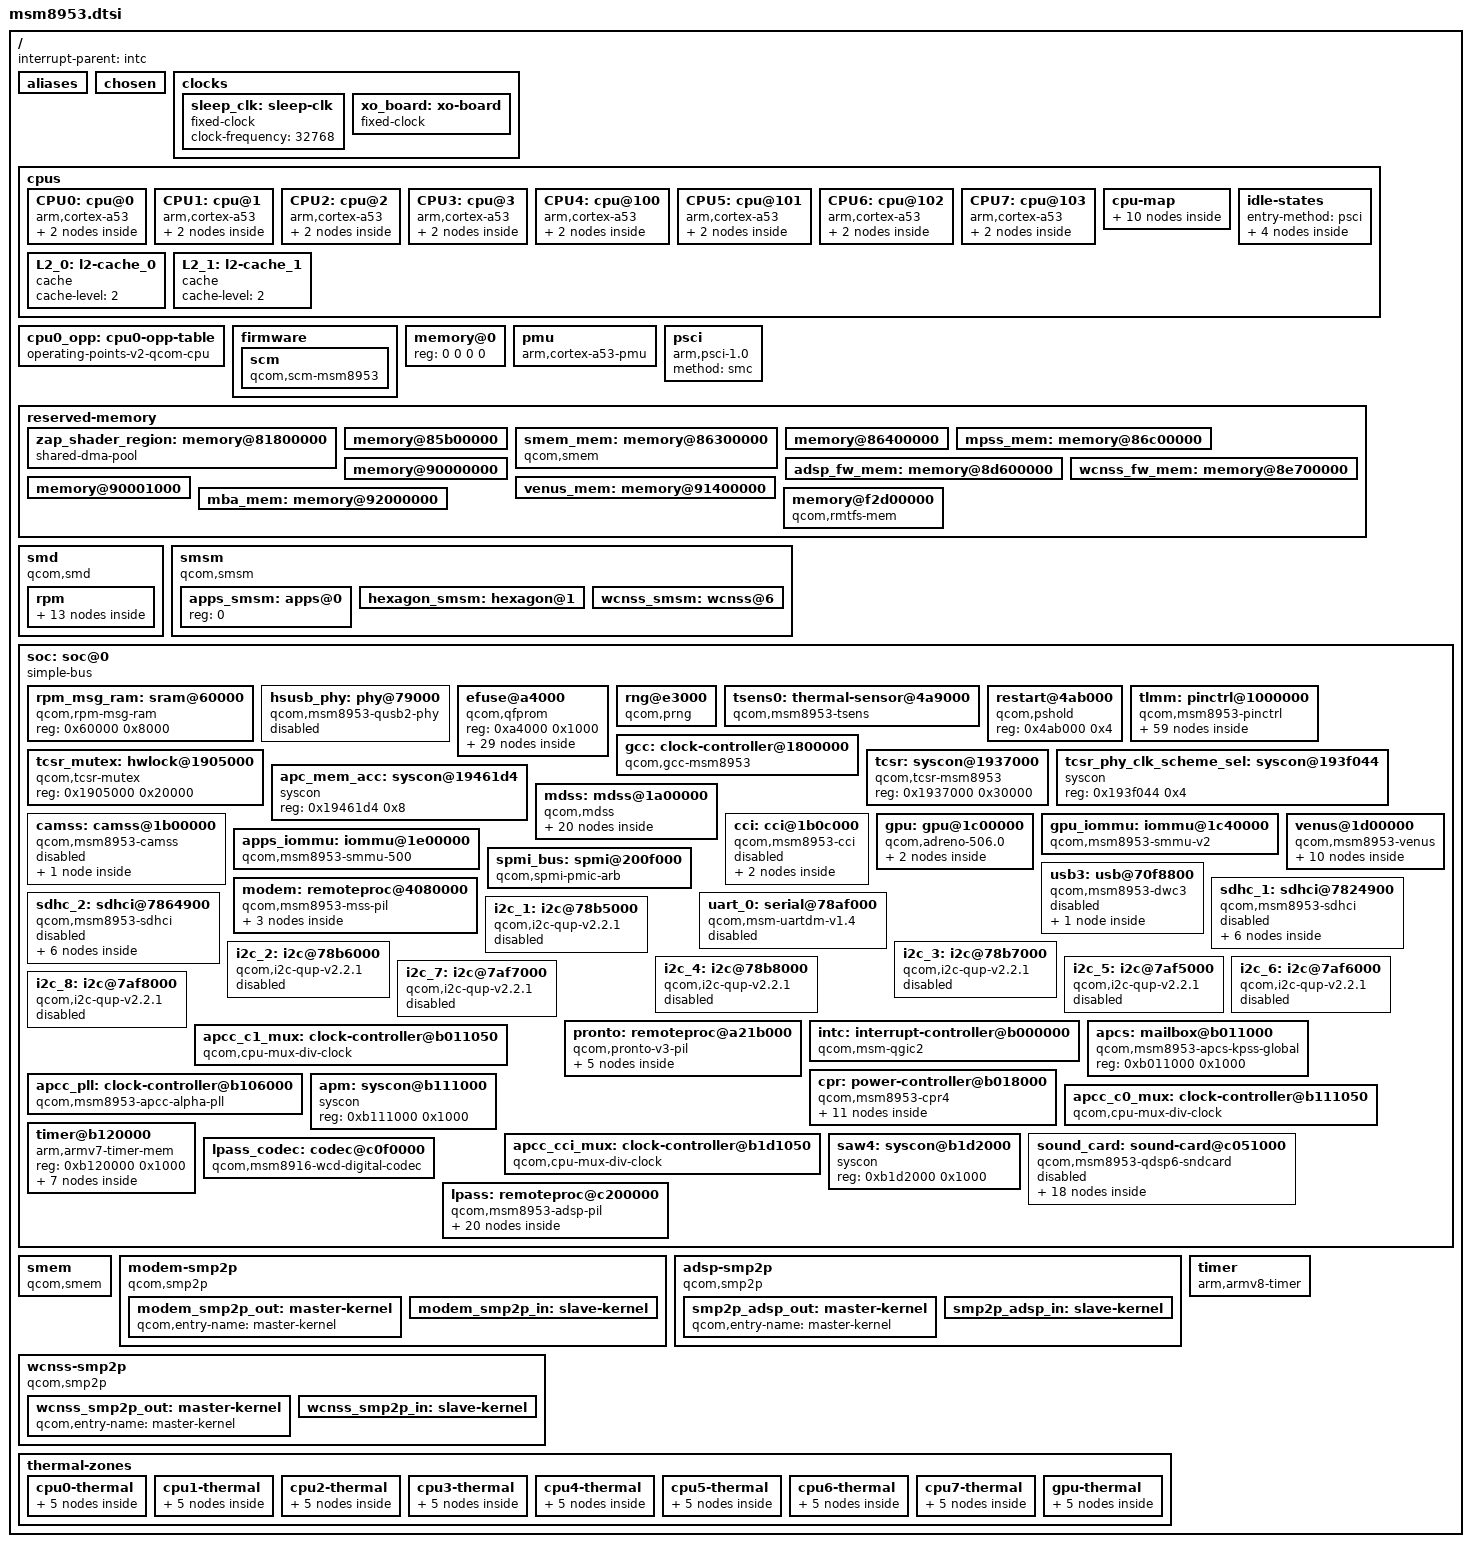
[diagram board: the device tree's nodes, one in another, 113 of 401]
// SPDX-License-Identifier: BSD-3-Clause
/* Copyright (c) 2022, The Linux Foundation. All rights reserved. */

#include <dt-bindings/clock/qcom,gcc-msm8953.h>
#include <dt-bindings/clock/qcom,rpmcc.h>
#include <dt-bindings/gpio/gpio.h>
#include <dt-bindings/interrupt-controller/arm-gic.h>
#include <dt-bindings/power/qcom-rpmpd.h>
#include <dt-bindings/soc/qcom,apr.h>
#include <dt-bindings/sound/qcom,q6afe.h>
#include <dt-bindings/sound/qcom,q6asm.h>
#include <dt-bindings/sound/qcom,q6voice.h>
#include <dt-bindings/thermal/thermal.h>

/ {
	interrupt-parent = <&intc>;

	#address-cells = <2>;
	#size-cells = <2>;

	aliases {
		mmc0 = &sdhc_1;
		mmc1 = &sdhc_2;
		i2c1 = &i2c_1;
		i2c2 = &i2c_2;
		i2c3 = &i2c_3;
		i2c4 = &i2c_4;
		i2c5 = &i2c_5;
		i2c6 = &i2c_6;
		i2c7 = &i2c_7;
		i2c8 = &i2c_8;
	};

	chosen { };

	clocks {
		sleep_clk: sleep-clk {
			compatible = "fixed-clock";
			#clock-cells = <0>;
			clock-frequency = <32768>;
		};

		xo_board: xo-board {
			compatible = "fixed-clock";
			#clock-cells = <0>;
			clock-frequency = <19200000>;
			clock-output-names = "xo";
		};
	};

	cpus {
		#address-cells = <1>;
		#size-cells = <0>;

		CPU0: cpu@0 {
			device_type = "cpu";
			compatible = "arm,cortex-a53";
			capacity-dmips-mhz = <1024>;
			cpu-idle-states = <&CPU_PC>,
					  <&CLUSTER_RET>,
					  <&CLUSTER_GDHS>,
					  <&CLUSTER_PC>;
			reg = <0x0>;
			enable-method = "psci";
			next-level-cache = <&L2_0>;
			#cooling-cells = <2>;
			clocks = <&apcc_pll>;
			clock-names = "cpu";
			operating-points-v2 = <&cpu0_opp>;
			power-domains = <&cpr 0>;
			power-domain-names = "cpr";
			l1-icache { compatible = "cache"; };
			l1-dcache { compatible = "cache"; };
		};

		CPU1: cpu@1 {
			device_type = "cpu";
			compatible = "arm,cortex-a53";
			capacity-dmips-mhz = <1024>;
			cpu-idle-states = <&CPU_PC>,
					  <&CLUSTER_RET>,
					  <&CLUSTER_GDHS>,
					  <&CLUSTER_PC>;
			reg = <0x1>;
			enable-method = "psci";
			next-level-cache = <&L2_0>;
			#cooling-cells = <2>;
			clocks = <&apcc_pll>;
			clock-names = "cpu";
			operating-points-v2 = <&cpu0_opp>;
			power-domains = <&cpr 0>;
			power-domain-names = "cpr";
			l1-icache { compatible = "cache"; };
			l1-dcache { compatible = "cache"; };
		};

		CPU2: cpu@2 {
			device_type = "cpu";
			compatible = "arm,cortex-a53";
			capacity-dmips-mhz = <1024>;
			cpu-idle-states = <&CPU_PC>,
					  <&CLUSTER_RET>,
					  <&CLUSTER_GDHS>,
					  <&CLUSTER_PC>;
			reg = <0x2>;
			enable-method = "psci";
			next-level-cache = <&L2_0>;
			#cooling-cells = <2>;
			clocks = <&apcc_pll>;
			clock-names = "cpu";
			operating-points-v2 = <&cpu0_opp>;
			power-domains = <&cpr 0>;
			power-domain-names = "cpr";
			l1-icache { compatible = "cache"; };
			l1-dcache { compatible = "cache"; };
		};

		CPU3: cpu@3 {
			device_type = "cpu";
			compatible = "arm,cortex-a53";
			capacity-dmips-mhz = <1024>;
			cpu-idle-states = <&CPU_PC>,
					  <&CLUSTER_RET>,
					  <&CLUSTER_GDHS>,
					  <&CLUSTER_PC>;
			reg = <0x3>;
			enable-method = "psci";
			next-level-cache = <&L2_0>;
			#cooling-cells = <2>;
			clocks = <&apcc_pll>;
			clock-names = "cpu";
			operating-points-v2 = <&cpu0_opp>;
			power-domains = <&cpr 0>;
			power-domain-names = "cpr";
			l1-icache { compatible = "cache"; };
			l1-dcache { compatible = "cache"; };
		};

		CPU4: cpu@100 {
			device_type = "cpu";
			compatible = "arm,cortex-a53";
			capacity-dmips-mhz = <1024>;
			cpu-idle-states = <&CPU_PC>,
					  <&CLUSTER_RET>,
					  <&CLUSTER_GDHS>,
					  <&CLUSTER_PC>;
			reg = <0x100>;
			enable-method = "psci";
			next-level-cache = <&L2_1>;
			#cooling-cells = <2>;
			clocks = <&apcc_pll>;
			clock-names = "cpu";
			operating-points-v2 = <&cpu0_opp>;
			power-domains = <&cpr 0>;
			power-domain-names = "cpr";
			l1-icache { compatible = "cache"; };
			l1-dcache { compatible = "cache"; };
		};

		CPU5: cpu@101 {
			device_type = "cpu";
			compatible = "arm,cortex-a53";
			capacity-dmips-mhz = <1024>;
			cpu-idle-states = <&CPU_PC>,
					  <&CLUSTER_RET>,
					  <&CLUSTER_GDHS>,
					  <&CLUSTER_PC>;
			reg = <0x101>;
			enable-method = "psci";
			next-level-cache = <&L2_1>;
			#cooling-cells = <2>;
			clocks = <&apcc_pll>;
			clock-names = "cpu";
			operating-points-v2 = <&cpu0_opp>;
			power-domains = <&cpr 0>;
			power-domain-names = "cpr";
			l1-icache { compatible = "cache"; };
			l1-dcache { compatible = "cache"; };
		};

		CPU6: cpu@102 {
			device_type = "cpu";
			compatible = "arm,cortex-a53";
			capacity-dmips-mhz = <1024>;
			cpu-idle-states = <&CPU_PC>,
					  <&CLUSTER_RET>,
					  <&CLUSTER_GDHS>,
					  <&CLUSTER_PC>;
			reg = <0x102>;
			enable-method = "psci";
			next-level-cache = <&L2_1>;
			#cooling-cells = <2>;
			clocks = <&apcc_pll>;
			clock-names = "cpu";
			operating-points-v2 = <&cpu0_opp>;
			power-domains = <&cpr 0>;
			power-domain-names = "cpr";
			l1-icache { compatible = "cache"; };
			l1-dcache { compatible = "cache"; };
		};

		CPU7: cpu@103 {
			device_type = "cpu";
			compatible = "arm,cortex-a53";
			capacity-dmips-mhz = <1024>;
			cpu-idle-states = <&CPU_PC>,
					  <&CLUSTER_RET>,
					  <&CLUSTER_GDHS>,
					  <&CLUSTER_PC>;
			reg = <0x103>;
			enable-method = "psci";
			next-level-cache = <&L2_1>;
			#cooling-cells = <2>;
			clocks = <&apcc_pll>;
			clock-names = "cpu";
			operating-points-v2 = <&cpu0_opp>;
			power-domains = <&cpr 0>;
			power-domain-names = "cpr";
			l1-icache { compatible = "cache"; };
			l1-dcache { compatible = "cache"; };
		};

		cpu-map {
			cluster0 {
				core0 {
					cpu = <&CPU0>;
				};
				core1 {
					cpu = <&CPU1>;
				};
				core2 {
					cpu = <&CPU2>;
				};
				core3 {
					cpu = <&CPU3>;
				};
			};

			cluster1 {
				core0 {
					cpu = <&CPU4>;
				};
				core1 {
					cpu = <&CPU5>;
				};
				core2 {
					cpu = <&CPU6>;
				};
				core3 {
					cpu = <&CPU7>;
				};
			};
		};

		idle-states {
			entry-method = "psci";

			CPU_PC: cpu-power-collapse {
				compatible = "qcom,idle-state";
				idle-state-name = "cpu-pc";
				arm,psci-suspend-param = <0x40000003>;
				entry-latency-us = <90>;
				exit-latency-us = <180>;
				min-residency-us = <400>;
				local-timer-stop;
			};

			CLUSTER_RET: cluster-retention {
				compatible = "qcom,idle-state";
				idle-state-name = "cluster-ret";
				arm,psci-suspend-param = <0x41000033>;
				entry-latency-us = <120>;
				exit-latency-us = <200>;
				min-residency-us = <1200>;
				local-timer-stop;
			};

			CLUSTER_GDHS: cluster-gdhs {
				compatible = "qcom,idle-state";
				idle-state-name = "cluster-gdhs";
				arm,psci-suspend-param = <0x41000043>;
				entry-latency-us = <150>;
				exit-latency-us = <220>;
				min-residency-us = <1800>;
				local-timer-stop;
			};

			CLUSTER_PC: cluster-power-collapse {
				compatible = "qcom,idle-state";
				idle-state-name = "cluster-pc";
				arm,psci-suspend-param = <0x41000053>;
				entry-latency-us = <270>;
				exit-latency-us = <430>;
				min-residency-us = <2500>;
				local-timer-stop;
			};
		};

		L2_0: l2-cache_0 {
			compatible = "cache";
			cache-level = <2>;
		};

		L2_1: l2-cache_1 {
			compatible = "cache";
			cache-level = <2>;
		};
	};

#define OPP(freqKhz, req, HW, peakBW, extra)		\
	opp-freqKhz##000 {				\
		opp-hz = /bits/ 64 <freqKhz##000>;	\
		opp-supported-hw = <HW>;		\
		required-opps = <&req>;			\
		extra; \
	}

#define BIN_625  0x04
#define BIN_626  0x81
#define BIN_ALL	 0xff

	cpu0_opp: cpu0-opp-table {
		compatible = "operating-points-v2-qcom-cpu",
			     "operating-points-v2-kryo-cpu";
		nvmem-cells = <&cpu_speed_bin>;
		opp-shared;

		OPP( 652800, cpr_opp1, BIN_ALL, 1611000, opp-suspend);
		OPP(1036800, cpr_opp2, BIN_ALL, 3221000, none);
		OPP(1248000, cpr_opp3, BIN_ALL, 4550000, none);
		OPP(1401600, cpr_opp4, BIN_ALL, 5859000, none);
		OPP(1689600, cpr_opp5, BIN_ALL, 6445000, none);
		OPP(1804800, cpr_opp6, BIN_ALL, 7104000, none);
		OPP(1958400, cpr_opp7, BIN_625, 7104000, none);
		OPP(2016000, cpr_opp8, BIN_625, 7104000, none);
		OPP(2150400, cpr_opp9, BIN_626, 7104000, none);
		OPP(2208000, cpr_opp10, BIN_626, 7104000, none);

	};

	firmware {
		scm: scm {
			compatible = "qcom,scm-msm8953";
			clocks = <&gcc GCC_CRYPTO_CLK>,
				 <&gcc GCC_CRYPTO_AXI_CLK>,
				 <&gcc GCC_CRYPTO_AHB_CLK>;
			clock-names = "core", "bus", "iface";
			#reset-cells = <1>;
		};
	};

	memory@0 {
		device_type = "memory";
		/* We expect the bootloader to fill in the reg */
		reg = <0 0 0 0>;
	};

	pmu {
		compatible = "arm,cortex-a53-pmu";
		interrupts = <GIC_PPI 7 (GIC_CPU_MASK_SIMPLE(8) | IRQ_TYPE_LEVEL_HIGH)>;
	};

	psci {
		compatible = "arm,psci-1.0";
		method = "smc";
	};

	reserved-memory {
		#address-cells = <2>;
		#size-cells = <2>;
		ranges;

		zap_shader_region: memory@81800000 {
			compatible = "shared-dma-pool";
			reg = <0x0 0x81800000 0x0 0x2000>;
			no-map;
		};

		memory@85b00000 {
			reg = <0x0 0x85b00000 0x0 0x800000>;
			no-map;
		};

		smem_mem: memory@86300000 {
			compatible = "qcom,smem";
			reg = <0x0 0x86300000 0x0 0x100000>;
			qcom,rpm-msg-ram = <&rpm_msg_ram>;
			hwlocks = <&tcsr_mutex 3>;
			no-map;
		};

		memory@86400000 {
			reg = <0x0 0x86400000 0x0 0x400000>;
			no-map;
		};

		mpss_mem: memory@86c00000 {
			reg = <0x0 0x86c00000 0x0 0x6a00000>;
			no-map;
		};

		adsp_fw_mem: memory@8d600000 {
			reg = <0x0 0x8d600000 0x0 0x1100000>;
			no-map;
		};

		wcnss_fw_mem: memory@8e700000 {
			reg = <0x0 0x8e700000 0x0 0x700000>;
			no-map;
		};

		memory@90000000 {
			reg = <0 0x90000000 0 0x1000>;
			no-map;
		};

		memory@90001000 {
			reg = <0x0 0x90001000 0x0 0x13ff000>;
			no-map;
		};

		venus_mem: memory@91400000 {
			reg = <0x0 0x91400000 0x0 0x700000>;
			no-map;
		};

		mba_mem: memory@92000000 {
			reg = <0x0 0x92000000 0x0 0x100000>;
			no-map;
		};

		memory@f2d00000 {
			compatible = "qcom,rmtfs-mem";
			reg = <0x0 0xf2d00000 0x0 0x180000>;
			no-map;

			qcom,client-id = <1>;
		};
	};

	smd {
		compatible = "qcom,smd";

		rpm {
			interrupts = <GIC_SPI 168 IRQ_TYPE_EDGE_RISING>;
			qcom,ipc = <&apcs 8 0>;
			qcom,smd-edge = <15>;

			rpm_requests: rpm_requests {
				compatible = "qcom,rpm-msm8953";
				qcom,smd-channels = "rpm_requests";

				rpmcc: rpmcc {
					compatible = "qcom,rpmcc-msm8953";
					clocks = <&xo_board>;
					clock-names = "xo";
					#clock-cells = <1>;
				};

				rpmpd: power-controller {
					compatible = "qcom,msm8953-rpmpd";
					#power-domain-cells = <1>;
					operating-points-v2 = <&rpmpd_opp_table>;

					clocks = <&xo_board>;
					clock-names = "ref";

					rpmpd_opp_table: opp-table {
						compatible = "operating-points-v2";

						rpmpd_opp_ret: opp1 {
							opp-level = <RPM_SMD_LEVEL_RETENTION>;
						};

						rpmpd_opp_ret_plus: opp2 {
							opp-level = <RPM_SMD_LEVEL_RETENTION_PLUS>;
						};

						rpmpd_opp_min_svs: opp3 {
							opp-level = <RPM_SMD_LEVEL_MIN_SVS>;
						};

						rpmpd_opp_low_svs: opp4 {
							opp-level = <RPM_SMD_LEVEL_LOW_SVS>;
						};

						rpmpd_opp_svs: opp5 {
							opp-level = <RPM_SMD_LEVEL_SVS>;
						};

						rpmpd_opp_svs_plus: opp6 {
							opp-level = <RPM_SMD_LEVEL_SVS_PLUS>;
						};

						rpmpd_opp_nom: opp7 {
							opp-level = <RPM_SMD_LEVEL_NOM>;
						};

						rpmpd_opp_nom_plus: opp8 {
							opp-level = <RPM_SMD_LEVEL_NOM_PLUS>;
						};

						rpmpd_opp_turbo: opp9 {
							opp-level = <RPM_SMD_LEVEL_TURBO>;
						};
					};
				};
			};
		};
	};

	smsm {
		compatible = "qcom,smsm";

		#address-cells = <1>;
		#size-cells = <0>;

		qcom,ipc-1 = <&apcs 8 13>;
		qcom,ipc-3 = <&apcs 8 19>;

		apps_smsm: apps@0 {
			reg = <0>;

			#qcom,smem-state-cells = <1>;
		};

		hexagon_smsm: hexagon@1 {
			reg = <1>;
			interrupts = <GIC_SPI 26 IRQ_TYPE_EDGE_RISING>;

			interrupt-controller;
			#interrupt-cells = <2>;
		};

		wcnss_smsm: wcnss@6 {
			reg = <6>;
			interrupts = <GIC_SPI 144 IRQ_TYPE_EDGE_RISING>;

			interrupt-controller;
			#interrupt-cells = <2>;
		};
	};

	soc: soc@0 {
		#address-cells = <1>;
		#size-cells = <1>;
		ranges = <0 0 0 0xffffffff>;
		compatible = "simple-bus";

		rpm_msg_ram: sram@60000 {
			compatible = "qcom,rpm-msg-ram";
			reg = <0x60000 0x8000>;
		};

		hsusb_phy: phy@79000 {
			compatible = "qcom,msm8953-qusb2-phy";
			reg = <0x79000 0x180>;
			#phy-cells = <0>;

			clocks = <&gcc GCC_USB_PHY_CFG_AHB_CLK>,
				 <&gcc GCC_QUSB_REF_CLK>;
			clock-names = "cfg_ahb", "ref";

			qcom,tcsr-syscon = <&tcsr_phy_clk_scheme_sel>;

			resets = <&gcc GCC_QUSB2_PHY_BCR>;

			status = "disabled";
		};

		efuse@a4000 {
			compatible = "qcom,qfprom";
			reg = <0xa4000 0x1000>;
			#address-cells = <1>;
			#size-cells = <1>;

			cpu_speed_bin: cpu_speed_bin@124 {
				reg = <0x125 1>;
				bits = <0 3>;
			};

			cpr_efuse_revision: fusing_rev@23c {
				reg = <0x23e 1>;
				bits = <5 3>;
			};

			cpr_efuse_ring1: ring1@248 {
				reg = <0x248 1>;
				bits = <0 4>;
			};

			cpr_efuse_ring2: ring2@248 {
				reg = <0x248 1>;
				bits = <4 4>;
			};

			cpr_efuse_ring3: ring3@249 {
				reg = <0x249 1>;
				bits = <0 4>;
			};

			cpr_efuse_ring4: ring4@249 {
				reg = <0x249 1>;
				bits = <4 4>;
			};

			cpr_efuse_ring5: ring5@24a {
				reg = <0x24a 1>;
				bits = <0 4>;
			};

			cpr_efuse_ring6: ring6@24a {
				reg = <0x24a 1>;
				bits = <4 4>;
			};

			cpr_efuse_ring7: ring7@24b {
				reg = <0x24b 1>;
				bits = <4 4>;
			};

			cpr_efuse_init_voltage1: ivoltage1@238 {
				reg = <0x238 2>;
				bits = <6 6>;
			};

			cpr_efuse_init_voltage2: ivoltage2@239 {
				reg = <0x239 2>;
				bits = <4 6>;
			};

			cpr_efuse_init_voltage3: ivoltage3@23a {
				reg = <0x23a 1>;
				bits = <2 6>;
			};

			cpr_efuse_init_voltage4: ivoltage4@23b {
				reg = <0x23b 1>;
				bits = <0 6>;
			};

			cpr_efuse_init_voltage5: ivoltage5@250 {
				reg = <0x250 1>;
				bits = <0 6>;
			};

			cpr_efuse_init_voltage6: ivoltage6@250 {
				reg = <0x250 2>;
				bits = <6 6>;
			};

			cpr_efuse_init_voltage7: ivoltage7@252 {
				reg = <0x252 1>;
				bits = <2 6>;
			};

			cpr_efuse_quot1: quot1@241 {
				reg = <0x241 2>;
				bits = <0 12>;
			};

			cpr_efuse_quot2: quot2@242 {
				reg = <0x242 2>;
				bits = <4 12>;
			};

			cpr_efuse_quot3: quot3@244 {
				reg = <0x244 2>;
				bits = <0 12>;
			};

			cpr_efuse_quot4: quot4@245 {
				reg = <0x245 2>;
				bits = <4 12>;
			};

			cpr_efuse_quot5: quot5@259 {
				reg = <0x259 4>;
				bits = <0 12>;
			};

			cpr_efuse_quot6: quot6@25a {
				reg = <0x25a 2>;
				bits = <4 12>;
			};

			cpr_efuse_quot7: quot7@25d {
				reg = <0x25d 2>;
				bits = <4 12>;
			};

			cpr_efuse_quot_offset1: qoffset1@23c {
				reg = <0x23c 1>;
				bits = <0 7>;
			};

			cpr_efuse_quot_offset2: qoffset2@23c {
				reg = <0x23c 2>;
				bits = <7 7>;
			};

			cpr_efuse_quot_offset3: qoffset3@23d {
				reg = <0x23d 2>;
				bits = <6 7>;
			};

			cpr_efuse_quot_offset4: qoffset4@253 {
				reg = <0x253 1>;
				bits = <0 7>;
			};

			cpr_efuse_quot_offset5: qoffset5@254 {
				reg = <0x254 1>;
				bits = <0 7>;
			};

			cpr_efuse_quot_offset6: qoffset6@255 {
				reg = <0x255 1>;
				bits = <0 7>;
			};
		};

		rng@e3000 {
			compatible = "qcom,prng";
			reg = <0x000e3000 0x1000>;
			clocks = <&gcc GCC_PRNG_AHB_CLK>;
			clock-names = "core";
		};

		tsens0: thermal-sensor@4a9000 {
			compatible = "qcom,msm8953-tsens", "qcom,tsens-v2";
			reg = <0x4a9000 0x1000>, /* TM */
			      <0x4a8000 0x1000>; /* SROT */
			#qcom,sensors = <16>;
			interrupts = <GIC_SPI 184 IRQ_TYPE_LEVEL_HIGH>,
				     <GIC_SPI 314 IRQ_TYPE_LEVEL_HIGH>;
			interrupt-names = "uplow", "critical";
			#thermal-sensor-cells = <1>;
		};

		restart@4ab000 {
			compatible = "qcom,pshold";
			reg = <0x4ab000 0x4>;
		};

		tlmm: pinctrl@1000000 {
			compatible = "qcom,msm8953-pinctrl";
			reg = <0x1000000 0x300000>;
			interrupts = <GIC_SPI 208 IRQ_TYPE_LEVEL_HIGH>;
			gpio-controller;
			gpio-ranges = <&tlmm 0 0 155>;
			#gpio-cells = <2>;
			interrupt-controller;
			#interrupt-cells = <2>;

			uart_console_active: uart-console-active-pins {
				pins = "gpio4", "gpio5";
				function = "blsp_uart2";
				drive-strength = <2>;
				bias-disable;
			};

			uart_console_sleep: uart-console-sleep-pins {
				pins = "gpio4", "gpio5";
				function = "blsp_uart2";
				drive-strength = <2>;
				bias-pull-down;
			};

			cci0_default: cci0-pins {
				pins = "gpio29", "gpio30";
				function = "cci_i2c";
				drive-strength = <2>;
				bias-disable;
			};

			cci1_default: cci1-pins {
				pins = "gpio31", "gpio32";
				function = "cci_i2c";
				drive-strength = <2>;
				bias-disable;
			};

			camss_mclk0_default: camss-mclk0-pins {
				pins = "gpio26";
				function = "cam_mclk";
				drive-strength = <2>;
				bias-disable;
			};

			camss_mclk1_default: camss-mclk1-pins {
				pins = "gpio27";
				function = "cam_mclk";
				drive-strength = <2>;
				bias-disable;
			};

			camss_mclk2_default: camss-mclk2-pins {
				pins = "gpio28";
				function = "cam_mclk";
				drive-strength = <2>;
				bias-disable;
			};

			mdss_te_default: mdss-te-pins {
				pins = "gpio24";
				function = "mdp_vsync";
				drive-strength = <2>;
				bias-pull-down;
			};

			/* SDC pin type */
			sdc1_clk_on: sdc1-clk-on-pins {
				pins = "sdc1_clk";
				bias-disable;
				drive-strength = <16>;
			};

			sdc1_clk_off: sdc1-clk-off-pins {
				pins = "sdc1_clk";
				bias-disable;
				drive-strength = <2>;
			};

			sdc1_cmd_on: sdc1-cmd-on-pins {
				pins = "sdc1_cmd";
				bias-disable;
				drive-strength = <10>;
			};

			sdc1_cmd_off: sdc1-cmd-off-pins {
				pins = "sdc1_cmd";
				bias-disable;
				drive-strength = <2>;
			};

			sdc1_data_on: sdc1-data-on-pins {
				pins = "sdc1_data";
				bias-pull-up;
				drive-strength = <10>;
			};

			sdc1_data_off: sdc1-data-off-pins {
				pins = "sdc1_data";
				bias-pull-up;
				drive-strength = <2>;
			};

			sdc1_rclk_on: sdc1-rclk-on-pins {
				pins = "sdc1_rclk";
				bias-pull-down;
			};

			sdc1_rclk_off: sdc1-rclk-off-pins {
				pins = "sdc1_rclk";
				bias-pull-down;
			};

			sdc2_clk_on: sdc2-clk-on-pins {
				pins = "sdc2_clk";
				drive-strength = <16>;
				bias-disable;
			};

			sdc2_clk_off: sdc2-clk-off-pins {
				pins = "sdc2_clk";
				bias-disable;
				drive-strength = <2>;
			};

			sdc2_cmd_on: sdc2-cmd-on-pins {
				pins = "sdc2_cmd";
				bias-pull-up;
				drive-strength = <10>;
			};

			sdc2_cmd_off: sdc2-cmd-off-pins {
				pins = "sdc2_cmd";
				bias-pull-up;
				drive-strength = <2>;
			};

			sdc2_data_on: sdc2-data-on-pins {
				pins = "sdc2_data";
				bias-pull-up;
				drive-strength = <10>;
			};

			sdc2_data_off: sdc2-data-off-pins {
				pins = "sdc2_data";
				bias-pull-up;
				drive-strength = <2>;
			};

			sdc2_cd_on: cd-on-pins {
				pins = "gpio133";
				function = "gpio";
				drive-strength = <2>;
				bias-pull-up;
			};

			sdc2_cd_off: cd-off-pins {
				pins = "gpio133";
				function = "gpio";
				drive-strength = <2>;
				bias-disable;
			};

			gpio_key_default: gpio-key-default-pins {
				pins = "gpio85";
				function = "gpio";
				drive-strength = <2>;
				bias-pull-up;
			};

			i2c_1_default: i2c-1-default-pins {
				pins = "gpio2", "gpio3";
				function = "blsp_i2c1";
				drive-strength = <2>;
				bias-disable;
			};

			i2c_1_sleep: i2c-1-sleep-pins {
				pins = "gpio2", "gpio3";
				function = "gpio";
				drive-strength = <2>;
				bias-disable;
			};

			i2c_2_default: i2c-2-default-pins {
				pins = "gpio6", "gpio7";
				function = "blsp_i2c2";
				drive-strength = <2>;
				bias-disable;
			};

			i2c_2_sleep: i2c-2-sleep-pins {
				pins = "gpio6", "gpio7";
				function = "gpio";
				drive-strength = <2>;
				bias-disable;
			};

			i2c_3_default: i2c-3-default-pins {
				pins = "gpio10", "gpio11";
				function = "blsp_i2c3";
				drive-strength = <2>;
				bias-disable;
			};

			i2c_3_sleep: i2c-3-sleep-pins {
				pins = "gpio10", "gpio11";
				function = "gpio";
				drive-strength = <2>;
				bias-disable;
			};

			i2c_4_default: i2c-4-default-pins {
				pins = "gpio14", "gpio15";
				function = "blsp_i2c4";
				drive-strength = <2>;
				bias-disable;
			};

			i2c_4_sleep: i2c-4-sleep-pins {
				pins = "gpio14", "gpio15";
				function = "gpio";
				drive-strength = <2>;
				bias-disable;
			};

			i2c_5_default: i2c-5-default-pins {
				pins = "gpio18", "gpio19";
				function = "blsp_i2c5";
				drive-strength = <2>;
				bias-disable;
			};

			i2c_5_sleep: i2c-5-sleep-pins {
				pins = "gpio18", "gpio19";
				function = "gpio";
				drive-strength = <2>;
				bias-disable;
			};

			i2c_6_default: i2c-6-default-pins {
				pins = "gpio22", "gpio23";
				function = "blsp_i2c6";
				drive-strength = <2>;
				bias-disable;
			};

			i2c_6_sleep: i2c-6-sleep-pins {
				pins = "gpio22", "gpio23";
				function = "gpio";
				drive-strength = <2>;
				bias-disable;
			};

			i2c_7_default: i2c-7-default-pins {
				pins = "gpio135", "gpio136";
				function = "blsp_i2c7";
				drive-strength = <2>;
				bias-disable;
			};

			i2c_7_sleep: i2c-7-sleep-pins {
				pins = "gpio135", "gpio136";
				function = "gpio";
				drive-strength = <2>;
				bias-disable;
			};

			i2c_8_default: i2c-8-default-pins {
				pins = "gpio98", "gpio99";
				function = "blsp_i2c8";
				drive-strength = <2>;
				bias-disable;
			};

			i2c_8_sleep: i2c-8-sleep-pins {
				pins = "gpio98", "gpio99";
				function = "gpio";
				drive-strength = <2>;
				bias-disable;
			};

			/* Active configuration of bus pins */
			wcnss_default: wcnss-default-pins {
				wcss_wlan2 {
					pins = "gpio76";
					function = "wcss_wlan2";
				};
				wcss_wlan1 {
					pins = "gpio77";
					function = "wcss_wlan1";
				};
				wcss_wlan0 {
					pins = "gpio78";
					function = "wcss_wlan0";
				};
				wcss_wlan {
					pins = "gpio79", "gpio80";
					function = "wcss_wlan";
				};

				pinconf {
					pins = "gpio76", "gpio77", "gpio78",
					       "gpio79", "gpio80";
					drive-strength = <6>;
					bias-pull-up;
				};
			};

			wcnss_sleep: wcnss-sleep-pins {
				wcss_wlan2 {
					pins = "gpio76";
					function = "wcss_wlan2";
				};
				wcss_wlan1 {
					pins = "gpio77";
					function = "wcss_wlan1";
				};
				wcss_wlan0 {
					pins = "gpio78";
					function = "wcss_wlan0";
				};
				wcss_wlan {
					pins = "gpio79", "gpio80";
					function = "wcss_wlan";
				};

				pinconf {
					pins = "gpio76", "gpio77",
						"gpio78", "gpio79",
						"gpio80";
					drive-strength = <2>;
					bias-pull-down;
				};
			};

			cdc_pdm_lines_2_act: pdm-lines-2-on-pins {
					pins = "gpio70", "gpio71", "gpio72";
					function = "cdc_pdm0";
					drive-strength = <8>;
			};

			cdc_pdm_lines_2_sus: pdm-lines-2-off-pins {
					pins = "gpio70", "gpio71", "gpio72";
					function = "cdc_pdm0";
					drive-strength = <2>;
					bias-disable;
			};

			cdc_pdm_lines_act: pdm-lines-on-pins {
					pins = "gpio69", "gpio73", "gpio74";
					function = "cdc_pdm0";
					drive-strength = <8>;
			};
			cdc_pdm_lines_sus: pdm-lines-off-pins {
					pins = "gpio69", "gpio73", "gpio74";
					function = "cdc_pdm0";
					drive-strength = <2>;
					bias-disable;
			};

			cdc_pdm_comp_lines_act: pdm-comp-lines-on-pins {
					pins = "gpio67", "gpio68";
					function = "cdc_pdm0";
					drive-strength = <8>;
			};

			cdc_pdm_comp_lines_sus: pdm-comp-lines-off-pins {
					pins = "gpio67", "gpio68";
					function = "cdc_pdm0";
					drive-strength = <2>;
					bias-disable;
			};
		};

		gcc: clock-controller@1800000 {
			compatible = "qcom,gcc-msm8953";
			reg = <0x1800000 0x80000>;
			#clock-cells = <1>;
			#reset-cells = <1>;
			#power-domain-cells = <1>;
			clocks = <&xo_board>,
				 <&sleep_clk>,
				 <0>,
				 <0>,
				 <0>,
				 <0>;
			clock-names = "xo",
				      "sleep",
				      "dsi0pll",
				      "dsi0pllbyte",
				      "dsi1pll",
				      "dsi1pllbyte";
		};

		tcsr_mutex: hwlock@1905000 {
			compatible = "qcom,tcsr-mutex";
			reg = <0x1905000 0x20000>;
			#hwlock-cells = <1>;
		};

		tcsr: syscon@1937000 {
			compatible = "qcom,tcsr-msm8953", "syscon";
			reg = <0x1937000 0x30000>;
		};

		tcsr_phy_clk_scheme_sel: syscon@193f044 {
			compatible = "syscon";
			reg = <0x193f044 0x4>;
		};

		apc_mem_acc: syscon@19461d4 {
			compatible = "syscon";
			reg = <0x19461d4 0x8>;
		};

		mdss: mdss@1a00000 {
			compatible = "qcom,mdss";

			reg = <0x1a00000 0x1000>,
			      <0x1ab0000 0x1040>;
			reg-names = "mdss_phys",
				    "vbif_phys";

			power-domains = <&gcc MDSS_GDSC>;
			interrupts = <GIC_SPI 72 IRQ_TYPE_LEVEL_HIGH>;

			interrupt-controller;
			#interrupt-cells = <1>;

			clocks = <&gcc GCC_MDSS_AHB_CLK>,
				 <&gcc GCC_MDSS_AXI_CLK>,
				 <&gcc GCC_MDSS_VSYNC_CLK>;
			clock-names = "iface",
				      "bus",
				      "vsync";

			#address-cells = <1>;
			#size-cells = <1>;
			ranges;

			dsi_phy0: dsi-phy@1a94400 {
				compatible = "qcom,dsi-phy-14nm-8953";
				reg = <0x1a94400 0x100>,
				      <0x1a94500 0x300>,
				      <0x1a94800 0x188>;

				reg-names = "dsi_phy",
				            "dsi_phy_lane",
				            "dsi_pll";

				#clock-cells = <1>;
				#phy-cells = <0>;

				clocks = <&gcc GCC_MDSS_AHB_CLK>;
				clock-names = "iface";
			};

			dsi_phy1: dsi-phy@1a96400 {
				compatible = "qcom,dsi-phy-14nm-8953";
				reg = <0x1a96400 0x100>,
				      <0x1a96500 0x300>,
				      <0x1a96800 0x188>;

				reg-names = "dsi_phy",
				            "dsi_phy_lane",
				            "dsi_pll";

				#clock-cells = <1>;
				#phy-cells = <0>;

				clocks = <&gcc GCC_MDSS_AHB_CLK>;
				clock-names = "iface";

				status = "disabled";
			};

			dsi0: dsi@1a94000 {
				compatible = "qcom,mdss-dsi-ctrl";
				reg = <0x1a94000 0x400>;
				reg-names = "dsi_ctrl";

				interrupt-parent = <&mdss>;
				interrupts = <4 0>;

				assigned-clocks = <&gcc BYTE0_CLK_SRC>,
						  <&gcc PCLK0_CLK_SRC>;
				assigned-clock-parents = <&dsi_phy0 0>,
							 <&dsi_phy0 1>;

				clocks = <&gcc GCC_MDSS_MDP_CLK>,
					 <&gcc GCC_MDSS_AHB_CLK>,
					 <&gcc GCC_MDSS_AXI_CLK>,
					 <&gcc GCC_MDSS_BYTE0_CLK>,
					 <&gcc GCC_MDSS_PCLK0_CLK>,
					 <&gcc GCC_MDSS_ESC0_CLK>;
				clock-names = "mdp_core",
					      "iface",
					      "bus",
					      "byte",
					      "pixel",
					      "core";

				phys = <&dsi_phy0>;
				phy-names = "dsi-phy";

				#address-cells = <1>;
				#size-cells = <0>;

				ports {
					#address-cells = <1>;
					#size-cells = <0>;

					port@0 {
						reg = <0>;
						dsi0_in: endpoint {
							remote-endpoint = <&mdp5_intf1_out>;
						};
					};

					port@1 {
						reg = <1>;
						dsi0_out: endpoint {
						};
					};
				};
			};

			dsi1: dsi@1a96000 {
				compatible = "qcom,mdss-dsi-ctrl";
				reg = <0x1a96000 0x400>;
				reg-names = "dsi_ctrl";

				interrupt-parent = <&mdss>;
				interrupts = <5 0>;

				assigned-clocks = <&gcc BYTE1_CLK_SRC>,
						  <&gcc PCLK1_CLK_SRC>;
				assigned-clock-parents = <&dsi_phy1 0>,
							 <&dsi_phy1 1>;

				clocks = <&gcc GCC_MDSS_MDP_CLK>,
					 <&gcc GCC_MDSS_AHB_CLK>,
					 <&gcc GCC_MDSS_AXI_CLK>,
					 <&gcc GCC_MDSS_BYTE1_CLK>,
					 <&gcc GCC_MDSS_PCLK1_CLK>,
					 <&gcc GCC_MDSS_ESC1_CLK>;
				clock-names = "mdp_core",
					      "iface",
					      "bus",
					      "byte",
					      "pixel",
					      "core";
				phys = <&dsi_phy1>;
				phy-names = "dsi-phy";

				status = "disabled";

				ports {
					#address-cells = <1>;
					#size-cells = <0>;

					port@0 {
						reg = <0>;
						dsi1_in: endpoint {
							remote-endpoint = <&mdp5_intf2_out>;
						};
					};

					port@1 {
						reg = <1>;
						dsi1_out: endpoint {
						};
					};
				};
			};

			mdp: mdp@1a01000 {
				compatible = "qcom,mdp5";
				reg = <0x1a01000 0x89000>;
				reg-names = "mdp_phys";

				interrupt-parent = <&mdss>;
				interrupts = <0 0>;

				power-domains = <&gcc MDSS_GDSC>;

				clocks = <&gcc GCC_MDSS_AHB_CLK>,
					 <&gcc GCC_MDSS_AXI_CLK>,
					 <&gcc GCC_MDSS_MDP_CLK>,
					 <&gcc GCC_MDSS_VSYNC_CLK>;
				clock-names = "iface",
					      "bus",
					      "core",
					      "vsync";

				iommus = <&apps_iommu 0xc00 0>;

				ports {
					#address-cells = <1>;
					#size-cells = <0>;

					port@0 {
						reg = <0>;
						mdp5_intf1_out: endpoint {
							remote-endpoint = <&dsi0_in>;
						};
					};

					port@1 {
						reg = <1>;
						mdp5_intf2_out: endpoint {
							remote-endpoint = <&dsi1_in>;
						};
					};
				};
			};
		};

		camss: camss@1b00000 {
			compatible = "qcom,msm8953-camss";
			reg = <0x1b34000 0x1000>,
			      <0x1b00030 0x4>,
			      <0x1b35000 0x1000>,
			      <0x1b00038 0x4>,
			      <0x1b36000 0x1000>,
			      <0x1b00040 0x4>,
			      <0x1b30000 0x100>,
			      <0x1b30400 0x100>,
			      <0x1b30800 0x100>,
			      <0x1b31000 0x500>,
			      <0x1b00020 0x10>,
			      <0x1b10000 0x1000>,
			      <0x1b14000 0x1000>;
			reg-names = "csiphy0",
				    "csiphy0_clk_mux",
				    "csiphy1",
				    "csiphy1_clk_mux",
				    "csiphy2",
				    "csiphy2_clk_mux",
				    "csid0",
				    "csid1",
				    "csid2",
				    "ispif",
				    "csi_clk_mux",
				    "vfe0",
				    "vfe1";
			interrupts = <GIC_SPI 78 IRQ_TYPE_EDGE_RISING>,
				     <GIC_SPI 79 IRQ_TYPE_EDGE_RISING>,
				     <GIC_SPI 315 IRQ_TYPE_EDGE_RISING>,
				     <GIC_SPI 51 IRQ_TYPE_EDGE_RISING>,
				     <GIC_SPI 52 IRQ_TYPE_EDGE_RISING>,
				     <GIC_SPI 153 IRQ_TYPE_EDGE_RISING>,
				     <GIC_SPI 55 IRQ_TYPE_EDGE_RISING>,
				     <GIC_SPI 57 IRQ_TYPE_EDGE_RISING>,
				     <GIC_SPI 29 IRQ_TYPE_EDGE_RISING>;
			interrupt-names = "csiphy0",
					  "csiphy1",
					  "csiphy2",
					  "csid0",
					  "csid1",
					  "csid2",
					  "ispif",
					  "vfe0",
					  "vfe1";
			power-domains = <&gcc VFE0_GDSC>,
					<&gcc VFE1_GDSC>;
			clocks = <&gcc GCC_CAMSS_TOP_AHB_CLK>,
				 <&gcc GCC_CAMSS_ISPIF_AHB_CLK>,
				 <&gcc GCC_CAMSS_MICRO_AHB_CLK>,
				 <&gcc GCC_CAMSS_CSI0PHYTIMER_CLK>,
				 <&gcc GCC_CAMSS_CSI1PHYTIMER_CLK>,
				 <&gcc GCC_CAMSS_CSI2PHYTIMER_CLK>,
				 <&gcc GCC_CAMSS_CSI0_AHB_CLK>,
				 <&gcc GCC_CAMSS_CSI0_CLK>,
				 <&gcc GCC_CAMSS_CSI0PHY_CLK>,
				 <&gcc GCC_CAMSS_CSI0PIX_CLK>,
				 <&gcc GCC_CAMSS_CSI0RDI_CLK>,
				 <&gcc GCC_CAMSS_CSI1_AHB_CLK>,
				 <&gcc GCC_CAMSS_CSI1_CLK>,
				 <&gcc GCC_CAMSS_CSI1PHY_CLK>,
				 <&gcc GCC_CAMSS_CSI1PIX_CLK>,
				 <&gcc GCC_CAMSS_CSI1RDI_CLK>,
				 <&gcc GCC_CAMSS_CSI2_AHB_CLK>,
				 <&gcc GCC_CAMSS_CSI2_CLK>,
				 <&gcc GCC_CAMSS_CSI2PHY_CLK>,
				 <&gcc GCC_CAMSS_CSI2PIX_CLK>,
				 <&gcc GCC_CAMSS_CSI2RDI_CLK>,
				 <&gcc GCC_CAMSS_AHB_CLK>,
				 <&gcc GCC_CAMSS_VFE0_CLK>,
				 <&gcc GCC_CAMSS_CSI_VFE0_CLK>,
				 <&gcc GCC_CAMSS_VFE0_AHB_CLK>,
				 <&gcc GCC_CAMSS_VFE0_AXI_CLK>,
				 <&gcc GCC_CAMSS_VFE1_CLK>,
				 <&gcc GCC_CAMSS_CSI_VFE1_CLK>,
				 <&gcc GCC_CAMSS_VFE1_AHB_CLK>,
				 <&gcc GCC_CAMSS_VFE1_AXI_CLK>;
			clock-names = "top_ahb",
				      "ispif_ahb",
				      "micro_ahb",
				      "csiphy0_timer",
				      "csiphy1_timer",
				      "csiphy2_timer",
				      "csi0_ahb",
				      "csi0",
				      "csi0_phy",
				      "csi0_pix",
				      "csi0_rdi",
				      "csi1_ahb",
				      "csi1",
				      "csi1_phy",
				      "csi1_pix",
				      "csi1_rdi",
				      "csi2_ahb",
				      "csi2",
				      "csi2_phy",
				      "csi2_pix",
				      "csi2_rdi",
				      "ahb",
				      "vfe0",
				      "csi_vfe0",
				      "vfe0_ahb",
				      "vfe0_axi",
				      "vfe1",
				      "csi_vfe1",
				      "vfe1_ahb",
				      "vfe1_axi";
			iommus = <&apps_iommu 0x400 0x0>,
				 <&apps_iommu 0x2800 0x0>;

			status = "disabled";

			ports {
				#address-cells = <1>;
				#size-cells = <0>;
			};
		};

		cci: cci@1b0c000 {
			compatible = "qcom,msm8953-cci";

			reg = <0x1b0c000 0x1000>;

			interrupts = <GIC_SPI 50 IRQ_TYPE_EDGE_RISING>;

			clocks = <&gcc GCC_CAMSS_TOP_AHB_CLK>,
				 <&gcc GCC_CAMSS_CCI_AHB_CLK>,
				 <&gcc GCC_CAMSS_CCI_CLK>,
				 <&gcc GCC_CAMSS_AHB_CLK>;
			clock-names = "camss_top_ahb",
				      "cci_ahb",
				      "cci",
				      "camss_ahb";

			assigned-clocks = <&gcc GCC_CAMSS_CCI_AHB_CLK>,
					  <&gcc GCC_CAMSS_CCI_CLK>;
			assigned-clock-rates = <80000000>, <19200000>;

			#address-cells = <1>;
			#size-cells = <0>;

			status = "disabled";

			cci_i2c0: i2c-bus@0 {
				reg = <0>;
				clock-frequency = <400000>;
				#address-cells = <1>;
				#size-cells = <0>;
			};

			cci_i2c1: i2c-bus@1 {
				reg = <1>;
				clock-frequency = <400000>;
				#address-cells = <1>;
				#size-cells = <0>;
			};
		};

		gpu: gpu@1c00000 {
			compatible = "qcom,adreno-506.0", "qcom,adreno";

			reg = <0x1c00000 0x40000>;
			reg-names = "kgsl_3d0_reg_memory";

			interrupts = <GIC_SPI 33 IRQ_TYPE_LEVEL_HIGH>;

			clocks = <&gcc GCC_OXILI_GFX3D_CLK>,
				 <&gcc GCC_OXILI_AHB_CLK>,
				 <&gcc GCC_BIMC_GFX_CLK>,
				 <&gcc GCC_BIMC_GPU_CLK>,
				 <&gcc GCC_OXILI_TIMER_CLK>,
				 <&gcc GCC_OXILI_AON_CLK>;

			clock-names = "core",
				      "iface",
				      "mem",
				      "mem_iface",
				      "rbbmtimer",
				      "alwayson";

			power-domains = <&gcc OXILI_CX_GDSC>,
					<&gcc OXILI_GX_GDSC>,
					<&rpmpd MSM8953_VDDCX>;
			power-domain-names = "cx", "gx", "pstate";

			iommus = <&gpu_iommu 0 1>;

			operating-points-v2 = <&gpu_opp_table>;

			#cooling-cells = <2>;

			gpu_opp_table: opp-table {
				compatible  ="operating-points-v2";

// TODO expand this
#define GPU_OPP(freq_khz, peakBW, lvl, supp)		\
	opp-##freq_khz##000 {				\
		opp-hz = /bits/ 64 <freq_khz##000>;	\
		opp-supported-hw = <supp>;		\
		opp-avg-kBps = <0>, <(peakBW/4)>;	\
		opp-peak-kBps = <peakBW>, <(peakBW/2)>;	\
		required-opps = <&lvl>;			\
	}

				GPU_OPP(200000, 1689600, rpmpd_opp_low_svs, 0xff);
				GPU_OPP(266670, 3072000, rpmpd_opp_svs, 0xff);
				GPU_OPP(320000, 3379200, rpmpd_opp_svs, 0xff);
				GPU_OPP(400000, 5376000, rpmpd_opp_svs_plus, 0xff);
				GPU_OPP(460800, 6144000, rpmpd_opp_nom, 0xff);
				GPU_OPP(510000, 6451200, rpmpd_opp_nom, 0xff);
				GPU_OPP(560000, 6758400, rpmpd_opp_nom_plus, 0xff);
				GPU_OPP(600000, 7449600, rpmpd_opp_turbo, 0xff);
				GPU_OPP(650000, 7449600, rpmpd_opp_turbo, 0xff);
			};

			zap-shader {
				memory-region = <&zap_shader_region>;
				firmware-name = "a506_zap.mdt";
			};
		};

		gpu_iommu: iommu@1c40000 {
			compatible = "qcom,msm8953-smmu-v2", "qcom,adreno-smmu", "qcom,smmu-v2";
			reg = <0x01c40000 0x10000>;

			clocks = <&gcc GCC_OXILI_AHB_CLK>,
				 <&gcc GCC_BIMC_GFX_CLK>;
			clock-names = "iface", "bus";

			#global-interrupts = <0>;
			interrupts = <GIC_SPI 225 IRQ_TYPE_LEVEL_HIGH>,
				     <GIC_SPI 232 IRQ_TYPE_LEVEL_HIGH>,
				     <GIC_SPI 233 IRQ_TYPE_LEVEL_HIGH>,
				     <GIC_SPI 234 IRQ_TYPE_LEVEL_HIGH>;

			power-domains = <&gcc OXILI_CX_GDSC>;

			qcom,iommu-secure-id = <18>;

			#iommu-cells = <2>;
		};

		venus@1d00000 {
			compatible = "qcom,msm8953-venus";
			reg = <0x1d00000 0xff000>;

			interrupts = <GIC_SPI 44 IRQ_TYPE_LEVEL_HIGH>;

			clocks = <&gcc GCC_VENUS0_VCODEC0_CLK>,
				 <&gcc GCC_VENUS0_AHB_CLK>,
				 <&gcc GCC_VENUS0_AXI_CLK>,
				 <&gcc GCC_VENUS0_CORE0_VCODEC0_CLK>;
			clock-names = "core", "iface", "bus", "vcodec0";

			operating-points-v2 = <&venus_opp_table>;

			power-domains = <&gcc VENUS_GDSC>,
					<&rpmpd MSM8953_VDDCX>;
			power-domain-names = "venus", "cx";

			iommus = <&apps_iommu 0x800 0x1>,
				 <&apps_iommu 0x807 0x0>,
				 <&apps_iommu 0x808 0x7>,
				 <&apps_iommu 0x810 0x1>,
				 <&apps_iommu 0x828 0x1>,
				 <&apps_iommu 0x82c 0x1>,
				 <&apps_iommu 0x821 0x10>;

			memory-region = <&venus_mem>;

			video-decoder {
				compatible = "venus-decoder";
				power-domains = <&gcc VENUS_CORE0_GDSC>;
			};

			video-encoder {
				compatible = "venus-encoder";
				power-domains = <&gcc VENUS_CORE0_GDSC>;
			};

			venus_opp_table: venus-opp-table {
				compatible = "operating-points-v2";

				opp-114290000 {
					opp-hz = /bits/ 64 <114290000>;
					required-opps = <&rpmpd_opp_low_svs>;
				};

				opp-228570000 {
					opp-hz = /bits/ 64 <228570000>;
					required-opps = <&rpmpd_opp_svs>;
				};

				opp-310000000 {
					opp-hz = /bits/ 64 <310000000>;
					required-opps = <&rpmpd_opp_svs_plus>;
				};

				opp-360000000 {
					opp-hz = /bits/ 64 <360000000>;
					required-opps = <&rpmpd_opp_nom>;
				};

				opp-400000000 {
					opp-hz = /bits/ 64 <400000000>;
					required-opps = <&rpmpd_opp_nom_plus>;
				};

				opp-465000000 {
					opp-hz = /bits/ 64 <465000000>;
					required-opps = <&rpmpd_opp_turbo>;
				};

				opp-540000000 {
					opp-hz = /bits/ 64 <540000000>;
					required-opps = <&rpmpd_opp_turbo>;
				};
			};
		};

		apps_iommu: iommu@1e00000 {
			compatible = "qcom,msm8953-smmu-500", "qcom,smmu-v2";
			reg = <0x1e00000 0x40000>;

			clocks = <&gcc GCC_SMMU_CFG_CLK>,
				 <&gcc GCC_APSS_TCU_ASYNC_CLK>;
			clock-names = "iface", "bus";

			#global-interrupts = <0>;
			interrupts = <GIC_SPI 253 IRQ_TYPE_LEVEL_HIGH>,
				     <GIC_SPI 254 IRQ_TYPE_LEVEL_HIGH>,
				     <GIC_SPI 255 IRQ_TYPE_LEVEL_HIGH>,
				     <GIC_SPI 53 IRQ_TYPE_LEVEL_HIGH>,
				     <GIC_SPI 54 IRQ_TYPE_LEVEL_HIGH>,
				     <GIC_SPI 58 IRQ_TYPE_LEVEL_HIGH>,
				     <GIC_SPI 60 IRQ_TYPE_LEVEL_HIGH>,
				     <GIC_SPI 61 IRQ_TYPE_LEVEL_HIGH>,
				     <GIC_SPI 76 IRQ_TYPE_LEVEL_HIGH>,
				     <GIC_SPI 77 IRQ_TYPE_LEVEL_HIGH>,
				     <GIC_SPI 80 IRQ_TYPE_LEVEL_HIGH>,
				     <GIC_SPI 94 IRQ_TYPE_LEVEL_HIGH>,
				     <GIC_SPI 101 IRQ_TYPE_LEVEL_HIGH>,
				     <GIC_SPI 102 IRQ_TYPE_LEVEL_HIGH>,
				     <GIC_SPI 103 IRQ_TYPE_LEVEL_HIGH>,
				     <GIC_SPI 104 IRQ_TYPE_LEVEL_HIGH>,
				     <GIC_SPI 105 IRQ_TYPE_LEVEL_HIGH>,
				     <GIC_SPI 106 IRQ_TYPE_LEVEL_HIGH>,
				     <GIC_SPI 109 IRQ_TYPE_LEVEL_HIGH>,
				     <GIC_SPI 110 IRQ_TYPE_LEVEL_HIGH>,
				     <GIC_SPI 111 IRQ_TYPE_LEVEL_HIGH>,
				     <GIC_SPI 112 IRQ_TYPE_LEVEL_HIGH>,
				     <GIC_SPI 113 IRQ_TYPE_LEVEL_HIGH>,
				     <GIC_SPI 114 IRQ_TYPE_LEVEL_HIGH>,
				     <GIC_SPI 115 IRQ_TYPE_LEVEL_HIGH>,
				     <GIC_SPI 116 IRQ_TYPE_LEVEL_HIGH>,
				     <GIC_SPI 117 IRQ_TYPE_LEVEL_HIGH>,
				     <GIC_SPI 118 IRQ_TYPE_LEVEL_HIGH>,
				     <GIC_SPI 119 IRQ_TYPE_LEVEL_HIGH>,
				     <GIC_SPI 120 IRQ_TYPE_LEVEL_HIGH>,
				     <GIC_SPI 121 IRQ_TYPE_LEVEL_HIGH>,
				     <GIC_SPI 122 IRQ_TYPE_LEVEL_HIGH>;

			qcom,iommu-secure-id = <17>;

			#iommu-cells = <2>;
		};

		spmi_bus: spmi@200f000 {
			compatible = "qcom,spmi-pmic-arb";
			reg = <0x200f000 0x1000>,
			      <0x2400000 0x800000>,
			      <0x2c00000 0x800000>,
			      <0x3800000 0x200000>,
			      <0x200a000 0x2100>;
			reg-names = "core", "chnls", "obsrvr", "intr", "cnfg";
			interrupt-names = "periph_irq";
			interrupts = <GIC_SPI 190 IRQ_TYPE_LEVEL_HIGH>;
			qcom,ee = <0>;
			qcom,channel = <0>;
			interrupt-controller;

			#interrupt-cells = <4>;
			#address-cells = <2>;
			#size-cells = <0>;
		};

		modem: remoteproc@4080000 {
			compatible = "qcom,msm8953-mss-pil";
			reg = <0x4080000 0x100>,
			      <0x4020000 0x040>;

			reg-names = "qdsp6", "rmb";

			interrupts-extended = <&intc 0 24 1>,
					      <&modem_smp2p_in 0 0>,
					      <&modem_smp2p_in 1 0>,
					      <&modem_smp2p_in 2 0>,
					      <&modem_smp2p_in 3 0>;
			interrupt-names = "wdog", "fatal", "ready",
					  "handover", "stop-ack";

			clocks = <&gcc GCC_MSS_CFG_AHB_CLK>,
				 <&gcc GCC_MSS_Q6_BIMC_AXI_CLK>,
				 <&gcc GCC_BOOT_ROM_AHB_CLK>,
				 <&xo_board>;
			clock-names = "iface", "bus", "mem", "xo";

			power-domains = <&rpmpd MSM8953_VDDCX>, <&rpmpd MSM8953_VDDMX>;
			power-domain-names = "cx", "mx";

			qcom,smem-states = <&modem_smp2p_out 0>;
			qcom,smem-state-names = "stop";

			resets = <&gcc GCC_MSS_BCR>;
			reset-names = "mss_restart";

			qcom,halt-regs = <&tcsr 0x18000 0x19000 0x1a000>;

			status = "okay";

			mba {
				memory-region = <&mba_mem>;
			};

			mpss {
				memory-region = <&mpss_mem>;
			};

			smd-edge {
				interrupts = <GIC_SPI 25 IRQ_TYPE_EDGE_RISING>;

				qcom,smd-edge = <0>;
				qcom,ipc = <&apcs 8 12>;
				qcom,remote-pid = <1>;

				label = "modem";
			};
		};

		usb3: usb@70f8800 {
			compatible = "qcom,msm8953-dwc3", "qcom,dwc3";
			reg = <0x70f8800 0x400>;
			#address-cells = <1>;
			#size-cells = <1>;
			ranges;

			interrupts = <GIC_SPI 136 IRQ_TYPE_LEVEL_HIGH>,
				     <GIC_SPI 220 IRQ_TYPE_LEVEL_HIGH>;
			interrupt-names = "hs_phy_irq", "ss_phy_irq";

			clocks = <&gcc GCC_USB_PHY_CFG_AHB_CLK>,
				 <&gcc GCC_USB30_MASTER_CLK>,
				 <&gcc GCC_PCNOC_USB3_AXI_CLK>,
				 <&gcc GCC_USB30_MOCK_UTMI_CLK>,
				 <&gcc GCC_USB30_SLEEP_CLK>;
			clock-names = "cfg_noc", "core", "iface",
				      "mock_utmi", "sleep";

			assigned-clocks = <&gcc GCC_USB30_MOCK_UTMI_CLK>,
					  <&gcc GCC_USB30_MASTER_CLK>;
			assigned-clock-rates = <19200000>, <133330000>;

			power-domains = <&gcc USB30_GDSC>;

			qcom,select-utmi-as-pipe-clk;

			status = "disabled";

			usb3_dwc3: usb@7000000 {
				compatible = "snps,dwc3";
				reg = <0x07000000 0xcc00>;
				interrupts = <GIC_SPI 140 IRQ_TYPE_LEVEL_HIGH>;
				phys = <&hsusb_phy>;
				phy-names = "usb2-phy";

				snps,usb2-gadget-lpm-disable;
				snps,dis-u1-entry-quirk;
				snps,dis-u2-entry-quirk;
				snps,is-utmi-l1-suspend;
				snps,hird-threshold = /bits/ 8 <0x00>;

				maximum-speed = "high-speed";
				phy_mode = "utmi";
			};
		};

		sdhc_1: sdhci@7824900 {
			compatible = "qcom,msm8953-sdhci", "qcom,sdhci-msm-v4";

			reg = <0x7824900 0x500>, <0x7824000 0x800>;
			reg-names = "hc_mem", "core_mem";

			interrupts = <GIC_SPI 123 IRQ_TYPE_LEVEL_HIGH>,
				     <GIC_SPI 138 IRQ_TYPE_LEVEL_HIGH>;
			interrupt-names = "hc_irq", "pwr_irq";

			clocks = <&gcc GCC_SDCC1_AHB_CLK>,
				 <&gcc GCC_SDCC1_APPS_CLK>,
				 <&xo_board>;
			clock-names = "iface", "core", "xo";

			power-domains = <&rpmpd MSM8953_VDDCX>;
			operating-points-v2 = <&sdhc1_opp_table>;

			pinctrl-names = "default", "sleep";
			pinctrl-0 = <&sdc1_clk_on &sdc1_cmd_on &sdc1_data_on &sdc1_rclk_on>;
			pinctrl-1 = <&sdc1_clk_off &sdc1_cmd_off &sdc1_data_off &sdc1_rclk_off>;

			mmc-hs200-1_8v;
			mmc-hs400-1_8v;
			mmc-ddr-1_8v;
			bus-width = <8>;
			non-removable;

			status = "disabled";

			sdhc1_opp_table: opp-table-sdhc1 {
				compatible = "operating-points-v2";

				opp-25000000 {
					opp-hz = /bits/ 64 <25000000>;
					required-opps = <&rpmpd_opp_low_svs>;
				};

				opp-50000000 {
					opp-hz = /bits/ 64 <50000000>;
					required-opps = <&rpmpd_opp_svs>;
				};

				opp-100000000 {
					opp-hz = /bits/ 64 <100000000>;
					required-opps = <&rpmpd_opp_svs>;
				};

				opp-192000000 {
					opp-hz = /bits/ 64 <192000000>;
					required-opps = <&rpmpd_opp_nom>;
				};

				opp-384000000 {
					opp-hz = /bits/ 64 <384000000>;
					required-opps = <&rpmpd_opp_nom>;
				};
			};
		};

		sdhc_2: sdhci@7864900 {
			compatible = "qcom,msm8953-sdhci", "qcom,sdhci-msm-v4";

			reg = <0x7864900 0x500>, <0x7864000 0x800>;
			reg-names = "hc_mem", "core_mem";

			interrupts = <GIC_SPI 125 IRQ_TYPE_LEVEL_HIGH>,
				     <GIC_SPI 221 IRQ_TYPE_LEVEL_HIGH>;
			interrupt-names = "hc_irq", "pwr_irq";

			clocks = <&gcc GCC_SDCC2_AHB_CLK>,
				 <&gcc GCC_SDCC2_APPS_CLK>,
				 <&xo_board>;
			clock-names = "iface", "core", "xo";

			power-domains = <&rpmpd MSM8953_VDDCX>;
			operating-points-v2 = <&sdhc2_opp_table>;

			pinctrl-names = "default", "sleep";
			pinctrl-0 = <&sdc2_clk_on &sdc2_cmd_on &sdc2_data_on>;
			pinctrl-1 = <&sdc2_clk_off &sdc2_cmd_off &sdc2_data_off>;

			bus-width = <4>;

			status = "disabled";

			sdhc2_opp_table: opp-table-sdhc2 {
				compatible = "operating-points-v2";

				opp-25000000 {
					opp-hz = /bits/ 64 <25000000>;
					required-opps = <&rpmpd_opp_low_svs>;
				};

				opp-50000000 {
					opp-hz = /bits/ 64 <50000000>;
					required-opps = <&rpmpd_opp_svs>;
				};

				opp-100000000 {
					opp-hz = /bits/ 64 <100000000>;
					required-opps = <&rpmpd_opp_svs>;
				};

				opp-177770000 {
					opp-hz = /bits/ 64 <177770000>;
					required-opps = <&rpmpd_opp_nom>;
				};

				opp-200000000 {
					opp-hz = /bits/ 64 <200000000>;
					required-opps = <&rpmpd_opp_nom>;
				};
			};
		};

		uart_0: serial@78af000 {
			compatible = "qcom,msm-uartdm-v1.4", "qcom,msm-uartdm";
			reg = <0x78af000 0x200>;
			interrupts = <GIC_SPI 107 IRQ_TYPE_LEVEL_HIGH>;
			clocks = <&gcc GCC_BLSP1_UART1_APPS_CLK>,
				 <&gcc GCC_BLSP1_AHB_CLK>;
			clock-names = "core", "iface";

			status = "disabled";
		};

		i2c_1: i2c@78b5000 {
			compatible = "qcom,i2c-qup-v2.2.1";
			reg = <0x78b5000 0x600>;
			interrupts = <GIC_SPI 95 IRQ_TYPE_LEVEL_HIGH>;
			clock-names = "iface", "core";
			clocks = <&gcc GCC_BLSP1_AHB_CLK>,
				 <&gcc GCC_BLSP1_QUP1_I2C_APPS_CLK>;

			pinctrl-names = "default", "sleep";
			pinctrl-0 = <&i2c_1_default>;
			pinctrl-1 = <&i2c_1_sleep>;

			#address-cells = <1>;
			#size-cells = <0>;

			status = "disabled";
		};

		i2c_2: i2c@78b6000 {
			compatible = "qcom,i2c-qup-v2.2.1";
			reg = <0x78b6000 0x600>;
			interrupts = <GIC_SPI 96 IRQ_TYPE_LEVEL_HIGH>;
			clock-names = "iface", "core";
			clocks = <&gcc GCC_BLSP1_AHB_CLK>,
				 <&gcc GCC_BLSP1_QUP2_I2C_APPS_CLK>;

			pinctrl-names = "default", "sleep";
			pinctrl-0 = <&i2c_2_default>;
			pinctrl-1 = <&i2c_2_sleep>;

			#address-cells = <1>;
			#size-cells = <0>;

			status = "disabled";
		};

		i2c_3: i2c@78b7000 {
			compatible = "qcom,i2c-qup-v2.2.1";
			reg = <0x78b7000 0x600>;
			interrupts = <GIC_SPI 97 IRQ_TYPE_LEVEL_HIGH>;
			clock-names = "iface", "core";
			clocks = <&gcc GCC_BLSP1_AHB_CLK>,
				 <&gcc GCC_BLSP1_QUP3_I2C_APPS_CLK>;
			pinctrl-names = "default", "sleep";
			pinctrl-0 = <&i2c_3_default>;
			pinctrl-1 = <&i2c_3_sleep>;

			#address-cells = <1>;
			#size-cells = <0>;

			status = "disabled";
		};

		i2c_4: i2c@78b8000 {
			compatible = "qcom,i2c-qup-v2.2.1";
			reg = <0x78b8000 0x600>;
			interrupts = <GIC_SPI 98 IRQ_TYPE_LEVEL_HIGH>;
			clock-names = "iface", "core";
			clocks = <&gcc GCC_BLSP1_AHB_CLK>,
				 <&gcc GCC_BLSP1_QUP4_I2C_APPS_CLK>;
			pinctrl-names = "default", "sleep";
			pinctrl-0 = <&i2c_4_default>;
			pinctrl-1 = <&i2c_4_sleep>;

			#address-cells = <1>;
			#size-cells = <0>;

			status = "disabled";
		};

		i2c_5: i2c@7af5000 {
			compatible = "qcom,i2c-qup-v2.2.1";
			reg = <0x7af5000 0x600>;
			interrupts = <GIC_SPI 299 IRQ_TYPE_LEVEL_HIGH>;
			clock-names = "iface", "core";
			clocks = <&gcc GCC_BLSP2_AHB_CLK>,
				 <&gcc GCC_BLSP2_QUP1_I2C_APPS_CLK>;
			pinctrl-names = "default", "sleep";
			pinctrl-0 = <&i2c_5_default>;
			pinctrl-1 = <&i2c_5_sleep>;

			#address-cells = <1>;
			#size-cells = <0>;

			status = "disabled";
		};

		i2c_6: i2c@7af6000 {
			compatible = "qcom,i2c-qup-v2.2.1";
			reg = <0x7af6000 0x600>;
			interrupts = <GIC_SPI 300 IRQ_TYPE_LEVEL_HIGH>;
			clock-names = "iface", "core";
			clocks = <&gcc GCC_BLSP2_AHB_CLK>,
				 <&gcc GCC_BLSP2_QUP2_I2C_APPS_CLK>;
			pinctrl-names = "default", "sleep";
			pinctrl-0 = <&i2c_6_default>;
			pinctrl-1 = <&i2c_6_sleep>;

			#address-cells = <1>;
			#size-cells = <0>;

			status = "disabled";
		};

		i2c_7: i2c@7af7000 {
			compatible = "qcom,i2c-qup-v2.2.1";
			reg = <0x7af7000 0x600>;
			interrupts = <GIC_SPI 301 IRQ_TYPE_LEVEL_HIGH>;
			clock-names = "iface", "core";
			clocks = <&gcc GCC_BLSP2_AHB_CLK>,
				 <&gcc GCC_BLSP2_QUP3_I2C_APPS_CLK>;
			pinctrl-names = "default", "sleep";
			pinctrl-0 = <&i2c_7_default>;
			pinctrl-1 = <&i2c_7_sleep>;

			#address-cells = <1>;
			#size-cells = <0>;

			status = "disabled";
		};

		i2c_8: i2c@7af8000 {
			compatible = "qcom,i2c-qup-v2.2.1";
			reg = <0x7af8000 0x600>;
			interrupts = <GIC_SPI 302 IRQ_TYPE_LEVEL_HIGH>;
			clock-names = "iface", "core";
			clocks = <&gcc GCC_BLSP2_AHB_CLK>,
				 <&gcc GCC_BLSP2_QUP4_I2C_APPS_CLK>;
			pinctrl-names = "default", "sleep";
			pinctrl-0 = <&i2c_8_default>;
			pinctrl-1 = <&i2c_8_sleep>;

			#address-cells = <1>;
			#size-cells = <0>;

			status = "disabled";
		};

		pronto: remoteproc@a21b000 {
			compatible = "qcom,pronto-v3-pil", "qcom,pronto";
			reg = <0xa204000 0x2000>,
			      <0xa202000 0x1000>,
			      <0xa21b000 0x3000>;
			reg-names = "ccu", "dxe", "pmu";

			memory-region = <&wcnss_fw_mem>;

			interrupts-extended = <&intc 0 149 IRQ_TYPE_EDGE_RISING>,
					      <&wcnss_smp2p_in 0 IRQ_TYPE_EDGE_RISING>,
					      <&wcnss_smp2p_in 1 IRQ_TYPE_EDGE_RISING>,
					      <&wcnss_smp2p_in 2 IRQ_TYPE_EDGE_RISING>,
					      <&wcnss_smp2p_in 3 IRQ_TYPE_EDGE_RISING>;
			interrupt-names = "wdog", "fatal", "ready", "handover", "stop-ack";

			power-domains = <&rpmpd MSM8953_VDDCX>, <&rpmpd MSM8953_VDDMX>;
			power-domain-names = "cx", "mx";

			qcom,state = <&wcnss_smp2p_out 0>;
			qcom,state-names = "stop";

			pinctrl-names = "default", "sleep";
			pinctrl-0 = <&wcnss_default>;
			pinctrl-1 = <&wcnss_sleep>;

			status = "okay";

			iris: iris {
				compatible = "qcom,wcn3660b";

				clocks = <&rpmcc RPM_SMD_RF_CLK2>;
				clock-names = "xo";
			};

			smd-edge {
				interrupts = <GIC_SPI 142 IRQ_TYPE_EDGE_RISING>;

				qcom,ipc = <&apcs 8 17>;
				qcom,smd-edge = <6>;
				qcom,remote-pid = <4>;

				label = "pronto";

				wcnss {
					compatible = "qcom,wcnss";
					qcom,smd-channels = "WCNSS_CTRL";

					qcom,mmio = <&pronto>;

					bt {
						compatible = "qcom,wcnss-bt";
					};

					wifi {
						compatible = "qcom,wcnss-wlan";

						interrupts = <GIC_SPI 145 IRQ_TYPE_LEVEL_HIGH>,
							     <GIC_SPI 146 IRQ_TYPE_LEVEL_HIGH>;
						interrupt-names = "tx", "rx";

						qcom,smem-states = <&apps_smsm 10>, <&apps_smsm 9>;
						qcom,smem-state-names = "tx-enable", "tx-rings-empty";
					};
				};
			};
		};

		intc: interrupt-controller@b000000 {
			compatible = "qcom,msm-qgic2";
			interrupt-controller;
			#interrupt-cells = <3>;
			reg = <0x0b000000 0x1000>, <0x0b002000 0x1000>;
		};

		apcs: mailbox@b011000 {
			compatible = "qcom,msm8953-apcs-kpss-global", "syscon";
			reg = <0xb011000 0x1000>;
			#mbox-cells = <1>;
		};

		apcc_c1_mux: clock-controller@b011050 {
			compatible = "qcom,cpu-mux-div-clock";
			reg = <0xb011050 0x10>;
			clocks = <&apcc_pll>, <&gcc GPLL0_EARLY>;
			qcom,mux-values = <5>, <4>;
			qcom,safe-div = <3>;
			clock-output-names = "apcc-c1-mux";
			assigned-clocks = <&apcc_c1_mux>;
			assigned-clock-parents = <&apcc_pll>;
			assigned-clock-rates = <883200000>;
			#clock-cells = <0>;
		};

		cpr: power-controller@b018000 {
			compatible = "qcom,msm8953-cpr4";

			nvmem-cells = <&cpr_efuse_quot_offset3>,
				      <&cpr_efuse_quot_offset2>,
				      <&cpr_efuse_quot_offset1>,
				      <&cpr_efuse_init_voltage4>,
				      <&cpr_efuse_init_voltage3>,
				      <&cpr_efuse_init_voltage2>,
				      <&cpr_efuse_init_voltage1>,
				      <&cpr_efuse_quot4>,
				      <&cpr_efuse_quot3>,
				      <&cpr_efuse_quot2>,
				      <&cpr_efuse_quot1>,
				      <&cpr_efuse_ring4>,
				      <&cpr_efuse_ring3>,
				      <&cpr_efuse_ring2>,
				      <&cpr_efuse_ring1>,
				      <&cpr_efuse_revision>,
				      <&cpu_speed_bin>;
			nvmem-cell-names = "cpr_thread0_quotient_offset2",
					   "cpr_thread0_quotient_offset3",
					   "cpr_thread0_quotient_offset4",
					   "cpr_thread0_init_voltage1",
					   "cpr_thread0_init_voltage2",
					   "cpr_thread0_init_voltage3",
					   "cpr_thread0_init_voltage4",
					   "cpr_thread0_quotient1",
					   "cpr_thread0_quotient2",
					   "cpr_thread0_quotient3",
					   "cpr_thread0_quotient4",
					   "cpr_thread0_ring_osc1",
					   "cpr_thread0_ring_osc2",
					   "cpr_thread0_ring_osc3",
					   "cpr_thread0_ring_osc4",
					   "cpr_fuse_revision",
					   "cpr_speed_bin";

			reg = <0x0b018000 0x4000>;
			reg-names = "cpr-iomem";

			interrupts = <GIC_SPI 15 IRQ_TYPE_EDGE_RISING>;

			clocks = <&xo_board>;
			clock-names = "ref";

			acc-syscon = <&apc_mem_acc>;
			apm-syscon = <&apm>;

			#power-domain-cells = <1>;
			operating-points-v2 = <&cpr_opp_table>;

			cpr_opp_table: cpr-opp-table {
				compatible = "operating-points-v2-qcom-level";

				cpr_opp1: opp1 {
					opp-level = <1>;
				};
				cpr_opp2: opp2 {
					opp-level = <2>;
				};
				cpr_opp3: opp3 {
					opp-level = <3>;
				};
				cpr_opp4: opp4 {
					opp-level = <4>;
				};
				cpr_opp5: opp5 {
					opp-level = <5>;
				};
				cpr_opp6: opp6 {
					opp-level = <6>;
				};
				cpr_opp7: opp7 {
					opp-level = <7>;
				};
				cpr_opp8: opp8 {
					opp-level = <8>;
				};
				cpr_opp9: opp9 {
					opp-level = <9>;
				};
				cpr_opp10: opp10 {
					opp-level = <10>;
				};
			};
		};

		apcc_pll: clock-controller@b106000 {
			compatible = "qcom,msm8953-apcc-alpha-pll";
			reg = <0xb116000 0x40>;
			qcom,vco-ranges = <0 652800000 2208000000>;
			clocks = <&xo_board>;
			clock-output-names = "apcc-pll";
			assigned-clocks = <&apcc_pll>;
			assigned-clock-rates = <883200000>;
			#clock-cells = <0>;
		};

		apm: syscon@b111000 {
			compatible = "syscon";
			reg = <0xb111000 0x1000>;
		};

		apcc_c0_mux: clock-controller@b111050 {
			compatible = "qcom,cpu-mux-div-clock";
			reg = <0xb111050 0x10>;
			clocks = <&apcc_pll>, <&gcc GPLL0_EARLY>;
			qcom,mux-values = <5>, <4>;
			qcom,safe-div = <3>;
			clock-output-names = "apcc-c0-mux";
			assigned-clocks = <&apcc_c0_mux>;
			assigned-clock-parents = <&apcc_pll>;
			assigned-clock-rates = <883200000>;
			#clock-cells = <0>;
		};


		apcc_cci_mux: clock-controller@b1d1050 {
			compatible = "qcom,cpu-mux-div-clock";
			reg = <0xb1d1050 0x10>;
			clocks = <&apcc_pll>, <&gcc GPLL0_EARLY>;
			qcom,mux-values = <5>, <4>;
			qcom,safe-div = <5>;
			clock-output-names = "apcc-cci-mux";
			assigned-clocks = <&apcc_cci_mux>;
			assigned-clock-parents = <&apcc_pll>;
			assigned-clock-rates = <(883200000 * 2 / 5)>;
			#clock-cells = <0>;
		};

		timer@b120000 {
			compatible = "arm,armv7-timer-mem";
			reg = <0xb120000 0x1000>;
			#address-cells = <0x01>;
			#size-cells = <0x01>;
			ranges;

			frame@b121000 {
				frame-number = <0>;
				interrupts = <GIC_SPI 8 IRQ_TYPE_LEVEL_HIGH>,
					     <GIC_SPI 7 IRQ_TYPE_LEVEL_HIGH>;
				reg = <0xb121000 0x1000>,
				      <0xb122000 0x1000>;
			};

			frame@b123000 {
				frame-number = <1>;
				interrupts = <GIC_SPI 9 IRQ_TYPE_LEVEL_HIGH>;
				reg = <0xb123000 0x1000>;
				status = "disabled";
			};

			frame@b124000 {
				frame-number = <2>;
				interrupts = <GIC_SPI 10 IRQ_TYPE_LEVEL_HIGH>;
				reg = <0xb124000 0x1000>;
				status = "disabled";
			};

			frame@b125000 {
				frame-number = <3>;
				interrupts = <GIC_SPI 11 IRQ_TYPE_LEVEL_HIGH>;
				reg = <0xb125000 0x1000>;
				status = "disabled";
			};

			frame@b126000 {
				frame-number = <4>;
				interrupts = <GIC_SPI 12 IRQ_TYPE_LEVEL_HIGH>;
				reg = <0xb126000 0x1000>;
				status = "disabled";
			};

			frame@b127000 {
				frame-number = <5>;
				interrupts = <GIC_SPI 13 IRQ_TYPE_LEVEL_HIGH>;
				reg = <0xb127000 0x1000>;
				status = "disabled";
			};

			frame@b128000 {
				frame-number = <6>;
				interrupts = <GIC_SPI 14 IRQ_TYPE_LEVEL_HIGH>;
				reg = <0xb128000 0x1000>;
				status = "disabled";
			};
		};

		saw4: syscon@b1d2000 {
			compatible = "syscon";
			reg = <0xb1d2000 0x1000>;
		};

		sound_card: sound-card@c051000 {
			compatible = "qcom,msm8953-qdsp6-sndcard";
			reg = <0xc051000 0x4>,
			      <0xc051004 0x4>,
			      <0xc055000 0x4>,
			      <0xc052000 0x4>;
			reg-names = "mic-iomux",
				    "spkr-iomux",
				    "pri-iomux",
				    "quin-iomux";

			audio-routing =
				"AMIC1", "MIC BIAS External1",
				"AMIC2", "MIC BIAS External2",
				"AMIC3", "MIC BIAS External1",
				"MM_DL1", "MultiMedia1 Playback",
				"MM_DL3", "MultiMedia3 Playback",
				"MM_DL4", "MultiMedia4 Playback",
				"MultiMedia2 Capture", "MM_UL2";

			status = "disabled";

			mm1-dai-link {
				link-name = "MultiMedia1";
				cpu {
					sound-dai = <&q6asmdai MSM_FRONTEND_DAI_MULTIMEDIA1>;
				};
			};

			mm2-dai-link {
				link-name = "MultiMedia2";
				cpu {
					sound-dai = <&q6asmdai MSM_FRONTEND_DAI_MULTIMEDIA2>;
				};
			};

			mm3-dai-link {
				link-name = "MultiMedia3";
				cpu {
					sound-dai = <&q6asmdai MSM_FRONTEND_DAI_MULTIMEDIA3>;
				};
			};

			mm4-dai-link {
				link-name = "MultiMedia4";
				cpu {
					sound-dai = <&q6asmdai MSM_FRONTEND_DAI_MULTIMEDIA4>;
				};
			};

			cs-voice-dai-link {
				link-name = "CS-Voice";
				cpu {
					sound-dai = <&q6voicedai CS_VOICE>;
				};
			};

			primary-mi2s-dai-link {
				link-name = "Primary MI2S";
				cpu {
					sound-dai = <&q6afedai PRIMARY_MI2S_RX>;
				};

				platform {
					sound-dai = <&q6routing>;
				};

				codec {
					sound-dai = <&lpass_codec 0>, <&wcd_codec 0>;
				};
			};

			tertiary-mi2s-dai-link {
				link-name = "Tertiary MI2S";
				cpu {
					sound-dai = <&q6afedai TERTIARY_MI2S_TX>;
				};

				platform {
					sound-dai = <&q6routing>;
				};

				codec {
					sound-dai = <&lpass_codec 1>, <&wcd_codec 1>;
				};
			};
		};

		lpass_codec: codec@c0f0000 {
			compatible = "qcom,msm8916-wcd-digital-codec";
			reg = <0xc0f0000 0x400>;
			#sound-dai-cells = <1>;

			clocks = <&q6afecc LPASS_CLK_ID_INTERNAL_DIGITAL_CODEC_CORE
					   LPASS_CLK_ATTRIBUTE_COUPLE_NO>,
				 <&xo_board>;
			clock-names = "mclk", "ahbix-clk";
		};

		lpass: remoteproc@c200000 {
			compatible = "qcom,msm8953-adsp-pil";
			reg = <0xc200000 0x100>;

			interrupts-extended = <&intc 0 293 IRQ_TYPE_EDGE_RISING>,
					      <&smp2p_adsp_in 0 IRQ_TYPE_EDGE_RISING>,
					      <&smp2p_adsp_in 1 IRQ_TYPE_EDGE_RISING>,
					      <&smp2p_adsp_in 2 IRQ_TYPE_EDGE_RISING>,
					      <&smp2p_adsp_in 3 IRQ_TYPE_EDGE_RISING>;
			interrupt-names = "wdog", "fatal", "ready",
					  "handover", "stop-ack";
			clocks = <&xo_board>;
			clock-names = "xo";

			power-domains = <&rpmpd MSM8953_VDDCX>;
			power-domain-names = "cx";

			memory-region = <&adsp_fw_mem>;

			qcom,smem-states = <&smp2p_adsp_out 0>;
			qcom,smem-state-names = "stop";

			smd-edge {
				interrupts = <GIC_SPI 289 IRQ_TYPE_EDGE_RISING>;

				label = "lpass";
				mboxes = <&apcs 8>;
				qcom,smd-edge = <1>;
				qcom,remote-pid = <2>;
				#address-cells = <1>;
				#size-cells = <0>;

				apr {
					compatible = "qcom,apr-v2";
					qcom,smd-channels = "apr_audio_svc";
					qcom,apr-domain = <APR_DOMAIN_ADSP>;
					#address-cells = <1>;
					#size-cells = <0>;

					q6core {
						reg = <APR_SVC_ADSP_CORE>;
						compatible = "qcom,q6core";
					};

					q6afe: q6afe {
						compatible = "qcom,q6afe";
						reg = <APR_SVC_AFE>;
						q6afedai: dais {
							compatible = "qcom,q6afe-dais";
							#address-cells = <1>;
							#size-cells = <0>;
							#sound-dai-cells = <1>;

							dai@16 {
								reg = <PRIMARY_MI2S_RX>;
								qcom,sd-lines = <0 1>;
							};

							dai@21 {
								reg = <TERTIARY_MI2S_TX>;
								qcom,sd-lines = <0 1>;
							};
						};
						q6afecc: clock-controller {
							compatible = "qcom,q6afe-clocks";
							#clock-cells = <2>;
						};
					};

					q6asm: q6asm {
						compatible = "qcom,q6asm";
						reg = <APR_SVC_ASM>;
						q6asmdai: dais {
							compatible = "qcom,q6asm-dais";
							#address-cells = <1>;
							#size-cells = <0>;
							#sound-dai-cells = <1>;

							dai@0 {
								reg = <MSM_FRONTEND_DAI_MULTIMEDIA1>;
							};

							dai@1 {
								reg = <MSM_FRONTEND_DAI_MULTIMEDIA2>;
							};

							dai@2 {
								reg = <MSM_FRONTEND_DAI_MULTIMEDIA3>;
							};

							dai@3 {
								reg = <MSM_FRONTEND_DAI_MULTIMEDIA4>;
								is-compress-dai;
							};
						};
					};

					q6adm: q6adm {
						compatible = "qcom,q6adm";
						reg = <APR_SVC_ADM>;
						q6routing: routing {
							compatible = "qcom,q6adm-routing";
							#sound-dai-cells = <0>;
						};
					};

					q6mvm: apr-service@9 {
						compatible = "qcom,q6mvm";
						reg = <APR_SVC_ADSP_MVM>;

						q6voicedai: dais {
							compatible = "qcom,q6voice-dais";
							#sound-dai-cells = <0>;
						};
					};

					q6cvs: apr-service@a {
						compatible = "qcom,q6cvs";
						reg = <APR_SVC_ADSP_CVS>;
					};

					q6cvp: apr-service@b {
						compatible = "qcom,q6cvp";
						reg = <APR_SVC_ADSP_CVP>;
					};
				};
			};
		};
	};

	smem {
		compatible = "qcom,smem";

		memory-region = <&smem_mem>;
		qcom,rpm-msg-ram = <&rpm_msg_ram>;

		hwlocks = <&tcsr_mutex 3>;
	};

	modem-smp2p {
		compatible = "qcom,smp2p";
		qcom,smem = <435>, <428>;

		interrupts = <GIC_SPI 27 IRQ_TYPE_EDGE_RISING>;

		qcom,ipc = <&apcs 8 14>;

		qcom,local-pid = <0>;
		qcom,remote-pid = <1>;

		modem_smp2p_out: master-kernel {
			qcom,entry-name = "master-kernel";

			#qcom,smem-state-cells = <1>;
		};

		modem_smp2p_in: slave-kernel {
			qcom,entry-name = "slave-kernel";

			interrupt-controller;
			#interrupt-cells = <2>;
		};
	};

	adsp-smp2p {
		compatible = "qcom,smp2p";
		qcom,smem = <443>, <429>;

		interrupts = <GIC_SPI 291 IRQ_TYPE_EDGE_RISING>;

		mboxes = <&apcs 10>;

		qcom,local-pid = <0>;
		qcom,remote-pid = <2>;

		smp2p_adsp_out: master-kernel {
			qcom,entry-name = "master-kernel";
			#qcom,smem-state-cells = <1>;
		};

		smp2p_adsp_in: slave-kernel {
			qcom,entry-name = "slave-kernel";

			interrupt-controller;
			#interrupt-cells = <2>;
		};
	};

	wcnss-smp2p {
		compatible = "qcom,smp2p";
		qcom,smem = <451>, <431>;

		interrupts = <GIC_SPI 143 IRQ_TYPE_EDGE_RISING>;

		qcom,ipc = <&apcs 8 18>;

		qcom,local-pid = <0>;
		qcom,remote-pid = <4>;

		wcnss_smp2p_out: master-kernel {
			qcom,entry-name = "master-kernel";

			#qcom,smem-state-cells = <1>;
		};

		wcnss_smp2p_in: slave-kernel {
			qcom,entry-name = "slave-kernel";

			interrupt-controller;
			#interrupt-cells = <2>;
		};
	};

	thermal-zones {
		cpu0-thermal {
			polling-delay-passive = <250>;
			polling-delay = <1000>;
			thermal-sensors = <&tsens0 9>;
			trips {
				cpu0_alert: trip-point0 {
					temperature = <80000>;
					hysteresis = <2000>;
					type = "passive";
				};
				cpu0_crit: crit {
					temperature = <100000>;
					hysteresis = <2000>;
					type = "critical";
				};
			};
			cooling-maps {
				map0 {
					trip = <&cpu0_alert>;
					cooling-device = <&CPU0 THERMAL_NO_LIMIT THERMAL_NO_LIMIT>;
				};
			};
		};
		cpu1-thermal {
			polling-delay-passive = <250>;
			polling-delay = <1000>;
			thermal-sensors = <&tsens0 10>;
			trips {
				cpu1_alert: trip-point0 {
					temperature = <80000>;
					hysteresis = <2000>;
					type = "passive";
				};
				cpu1_crit: crit {
					temperature = <100000>;
					hysteresis = <2000>;
					type = "critical";
				};
			};
			cooling-maps {
				map0 {
					trip = <&cpu1_alert>;
					cooling-device = <&CPU1 THERMAL_NO_LIMIT THERMAL_NO_LIMIT>;
				};
			};
		};
		cpu2-thermal {
			polling-delay-passive = <250>;
			polling-delay = <1000>;
			thermal-sensors = <&tsens0 11>;
			trips {
				cpu2_alert: trip-point0 {
					temperature = <80000>;
					hysteresis = <2000>;
					type = "passive";
				};
				cpu2_crit: crit {
					temperature = <100000>;
					hysteresis = <2000>;
					type = "critical";
				};
			};
			cooling-maps {
				map0 {
					trip = <&cpu2_alert>;
					cooling-device = <&CPU2 THERMAL_NO_LIMIT THERMAL_NO_LIMIT>;
				};
			};
		};
		cpu3-thermal {
			polling-delay-passive = <250>;
			polling-delay = <1000>;
			thermal-sensors = <&tsens0 12>;
			trips {
				cpu3_alert: trip-point0 {
					temperature = <80000>;
					hysteresis = <2000>;
					type = "passive";
				};
				cpu3_crit: crit {
					temperature = <100000>;
					hysteresis = <2000>;
					type = "critical";
				};
			};
			cooling-maps {
				map0 {
					trip = <&cpu3_alert>;
					cooling-device = <&CPU3 THERMAL_NO_LIMIT THERMAL_NO_LIMIT>;
				};
			};
		};
		cpu4-thermal {
			polling-delay-passive = <250>;
			polling-delay = <1000>;
			thermal-sensors = <&tsens0 4>;
			trips {
				cpu4_alert: trip-point0 {
					temperature = <80000>;
					hysteresis = <2000>;
					type = "passive";
				};
				cpu4_crit: crit {
					temperature = <100000>;
					hysteresis = <2000>;
					type = "critical";
				};
			};
			cooling-maps {
				map0 {
					trip = <&cpu4_alert>;
					cooling-device = <&CPU4 THERMAL_NO_LIMIT THERMAL_NO_LIMIT>;
				};
			};
		};
		cpu5-thermal {
			polling-delay-passive = <250>;
			polling-delay = <1000>;
			thermal-sensors = <&tsens0 5>;
			trips {
				cpu5_alert: trip-point0 {
					temperature = <80000>;
					hysteresis = <2000>;
					type = "passive";
				};
				cpu5_crit: crit {
					temperature = <100000>;
					hysteresis = <2000>;
					type = "critical";
				};
			};
			cooling-maps {
				map0 {
					trip = <&cpu5_alert>;
					cooling-device = <&CPU5 THERMAL_NO_LIMIT THERMAL_NO_LIMIT>;
				};
			};
		};
		cpu6-thermal {
			polling-delay-passive = <250>;
			polling-delay = <1000>;
			thermal-sensors = <&tsens0 6>;
			trips {
				cpu6_alert: trip-point0 {
					temperature = <80000>;
					hysteresis = <2000>;
					type = "passive";
				};
				cpu6_crit: crit {
					temperature = <100000>;
					hysteresis = <2000>;
					type = "critical";
				};
			};
			cooling-maps {
				map0 {
					trip = <&cpu6_alert>;
					cooling-device = <&CPU6 THERMAL_NO_LIMIT THERMAL_NO_LIMIT>;
				};
			};
		};
		cpu7-thermal {
			polling-delay-passive = <250>;
			polling-delay = <1000>;
			thermal-sensors = <&tsens0 7>;
			trips {
				cpu7_alert: trip-point0 {
					temperature = <80000>;
					hysteresis = <2000>;
					type = "passive";
				};
				cpu7_crit: crit {
					temperature = <100000>;
					hysteresis = <2000>;
					type = "critical";
				};
			};
			cooling-maps {
				map0 {
					trip = <&cpu7_alert>;
					cooling-device = <&CPU7 THERMAL_NO_LIMIT THERMAL_NO_LIMIT>;
				};
			};
		};
		gpu-thermal {
			polling-delay-passive = <250>;
			polling-delay = <1000>;
			thermal-sensors = <&tsens0 15>;
			trips {
				gpu_alert: trip-point@0 {
					temperature = <70000>;
					hysteresis = <2000>;
					type = "passive";
				};
				gpu_crit: crit {
					temperature = <90000>;
					hysteresis = <2000>;
					type = "critical";
				};
			};
			cooling-maps {
				map0 {
					trip = <&gpu_alert>;
					cooling-device = <&gpu THERMAL_NO_LIMIT THERMAL_NO_LIMIT>;
				};
			};
		};
	};

	timer {
		compatible = "arm,armv8-timer";
		interrupts = <GIC_PPI 2 (GIC_CPU_MASK_SIMPLE(8) | IRQ_TYPE_LEVEL_LOW)>,
			     <GIC_PPI 3 (GIC_CPU_MASK_SIMPLE(8) | IRQ_TYPE_LEVEL_LOW)>,
			     <GIC_PPI 4 (GIC_CPU_MASK_SIMPLE(8) | IRQ_TYPE_LEVEL_LOW)>,
			     <GIC_PPI 1 (GIC_CPU_MASK_SIMPLE(8) | IRQ_TYPE_LEVEL_LOW)>;
	};
};
